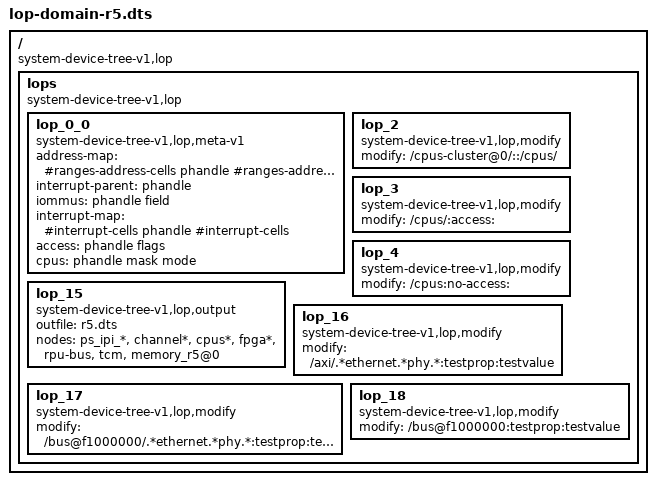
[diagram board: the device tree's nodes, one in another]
/*
 * Copyright (c) 2019,2020 Xilinx Inc. All rights reserved.
 *
 * Author:
 *       Bruce Ashfield <bruce.ashfield@xilinx.com>
 *
 * SPDX-License-Identifier: BSD-3-Clause
 */

/dts-v1/;

/ {
        compatible = "system-device-tree-v1,lop";
        lops {
                compatible = "system-device-tree-v1,lop";
                lop_0_0 {
                        compatible = "system-device-tree-v1,lop,meta-v1","phandle-desc-v1";
                        address-map = "#ranges-address-cells phandle #ranges-address-cells #ranges-size-cells";
                        interrupt-parent = "phandle";
                        iommus = "phandle field";
                        interrupt-map = "#interrupt-cells phandle #interrupt-cells";
                        access = "phandle flags";
                        cpus = "phandle mask mode";
                };
                lop_2 {
                        // node name modify
                        compatible = "system-device-tree-v1,lop,modify";
                        //modify = "/cpus_r5::";
                        modify = "/cpus-cluster@0/::/cpus/";
                        //noexec;
                };
                lop_3 {
                        compatible = "system-device-tree-v1,lop,modify";
                        // format is: "path":"property":"replacement"
                        //    - modify to "nothing", is a remove operation
                        //    - modify with no property is node operation (rename or remove)
                        modify = "/cpus/:access:";
                };
                lop_4 {
                        // modify to "nothing", is a remove operation
                        compatible = "system-device-tree-v1,lop,modify";
                        modify = "/cpus:no-access:";
                };
                  lop_15 {
                         compatible = "system-device-tree-v1,lop,output";
                         outfile = "r5.dts";
                         // * is "all nodes"
                         nodes = "ps_ipi_*", "channel*", "cpus*","fpga*","rpu-bus","tcm","memory_r5@0";
                  };

                  lop_16 {
                         compatible = "system-device-tree-v1,lop,modify";
                         modify = "/axi/.*ethernet.*phy.*:testprop:testvalue";
                  };
                  lop_17 {
                         compatible = "system-device-tree-v1,lop,modify";
                         modify = "/bus@f1000000/.*ethernet.*phy.*:testprop:testvaluenew";
                  };
                  lop_18 {
                         compatible = "system-device-tree-v1,lop,modify";
                         modify = "/bus@f1000000:testprop:testvalue";
                  };
        };
};
